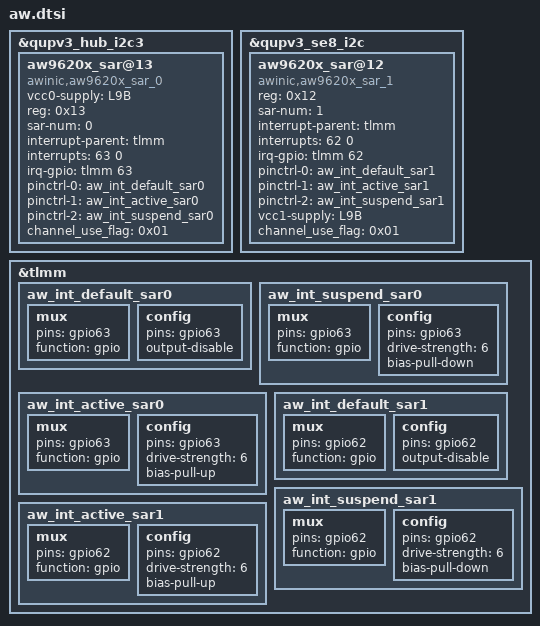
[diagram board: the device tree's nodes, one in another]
&qupv3_hub_i2c3 {
	    status = "ok";
		aw9620x_sar@13 {
			compatible = "awinic,aw9620x_sar_0";
			vcc0-supply = <&L9B>;
			reg = <0x13>;
			sar-num = < 0 >;
			interrupt-parent = < &tlmm >;
			interrupts = <63 0>;
			irq-gpio = <&tlmm 63 0>;
			pinctrl-names = "aw_int_default_sar0", "aw_int_active_sar0", "aw_int_suspend_sar0";
			pinctrl-0 = <&aw_int_default_sar0>;
			pinctrl-1 = <&aw_int_active_sar0>;
			pinctrl-2 = <&aw_int_suspend_sar0>;
			channel_use_flag = <0x01>;
			status = "okay";
		};
};
&qupv3_se8_i2c {
		status = "ok";
		aw9620x_sar@12 {
			compatible = "awinic,aw9620x_sar_1";
			reg = < 0x12 >;
			sar-num = < 1 >;
			interrupt-parent = < &tlmm >;
			interrupts = <62 0>;
			irq-gpio = <&tlmm 62 0>;
			pinctrl-names = "aw_int_default_sar1", "aw_int_active_sar1", "aw_int_suspend_sar1";
			pinctrl-0 = <&aw_int_default_sar1>;
			pinctrl-1 = <&aw_int_active_sar1>;
			pinctrl-2 = <&aw_int_suspend_sar1>;
			vcc1-supply = <&L9B>;
			channel_use_flag = <0x01>;
			status = "okay";
		};
};
&tlmm {
	
		aw_int_default_sar0: aw_int_default_sar0 {

			mux {
				pins = "gpio63";
				function = "gpio";
			};
			config {
				pins = "gpio63";
				output-disable;
			};
		};
		aw_int_suspend_sar0: aw_int_suspend_sar0 {
		   mux {
			   pins = "gpio63";
			   function = "gpio";
		   };
		 config {
			  pins = "gpio63";
			  drive-strength = <6>;
			  bias-pull-down;
		   };
		};
		aw_int_active_sar0: aw_int_active_sar0 {
		  mux {
			  pins = "gpio63";
			  function = "gpio";
		   };
		   config {
			 pins = "gpio63";
			 drive-strength = <6>;
			 bias-pull-up;
		   };
		};
	aw_int_default_sar1: aw_int_default_sar1 {

       mux {
           pins = "gpio62";
           function = "gpio";
       };
      config {
           pins = "gpio62";
           output-disable;
       };
    };
    aw_int_suspend_sar1: aw_int_suspend_sar1 {
       mux {
           pins = "gpio62";
           function = "gpio";
       };
     config {
          pins = "gpio62";
          drive-strength = <6>;
          bias-pull-down;
       };
    };
    aw_int_active_sar1: aw_int_active_sar1 {
      mux {
          pins = "gpio62";
          function = "gpio";
       };
    config {
         pins = "gpio62";
         drive-strength = <6>;
         bias-pull-up;
       };
    };

};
